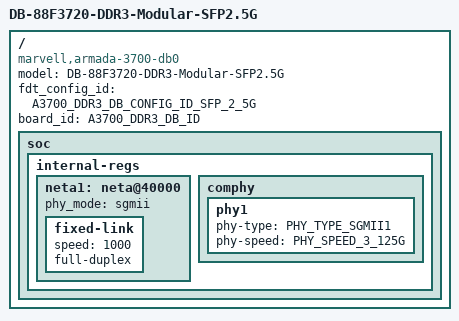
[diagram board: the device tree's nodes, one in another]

#include "armada-3700-ddr3-db.dts"

/* detail board setup:
 * Pcie Jumper slot	:	DB-88F3720-PCIe-mPCIe-Jumper
 * SGMII module slot	:	DB-88F3720-SerDes-Jumper
 * RGMII module slot	:	DB-88F3720-PHY module
 * eMMC slot		:	DB-88F3720-eMMC_NAND module
 * SDIO slot		:	DB-88F3720-SDcard module
 *
 * PHY0 (USB3/SGMII1)	:	SGMII1_Ethernet via SFP2.5G (1 Lane)
 * PHY1 (PCIe/SGMII0)	:	PCIe (WiFi via mini_PCIe module)
 * PHY2 (SATA)		:	SATA
 * RGMII		:	Ethernet via PHY (1 Lane)
 * USB2 Port 0		:	USB2 only
 * USB2 Port 1		:	USB2 Host
 * eMMC*		:	eMMC NAND
 * SDIO*		:	SD card
 * BOOT device*		:	SPI Flash
*/

/ {
	model = "DB-88F3720-DDR3-Modular-SFP2.5G";
	compatible = "marvell,armada-3700-db0", "marvell,armada-3700";
	fdt_config_id = <A3700_DDR3_DB_CONFIG_ID_SFP_2_5G>;
	board_id = <A3700_DDR3_DB_ID>;

	soc {
		internal-regs {
			neta1: neta@40000 {
				status = "okay";
				phy_mode = "sgmii";
				fixed-link {
					/* Here "speed" is set to 1000, GBE MAC is running in 1G mode,
					 * but the actuall PHY speed may be 1 Gbps or 2.5 Gbps,
					 * it's up to the corresponding SERDES speed in comphy node.
					 * If SERDES speed is set to 3.125G, it implies sgmii 2.5 Gbps;
					 * if SERDES speed is set to 1.25G, it implies sgmii 1 Gbps. */
					speed = <1000>;
					full-duplex;
				};
			};
			comphy {
				phy1 {
					phy-type = <PHY_TYPE_SGMII1>;
					phy-speed = <PHY_SPEED_3_125G>;
				};
			};
		};
	};
};
